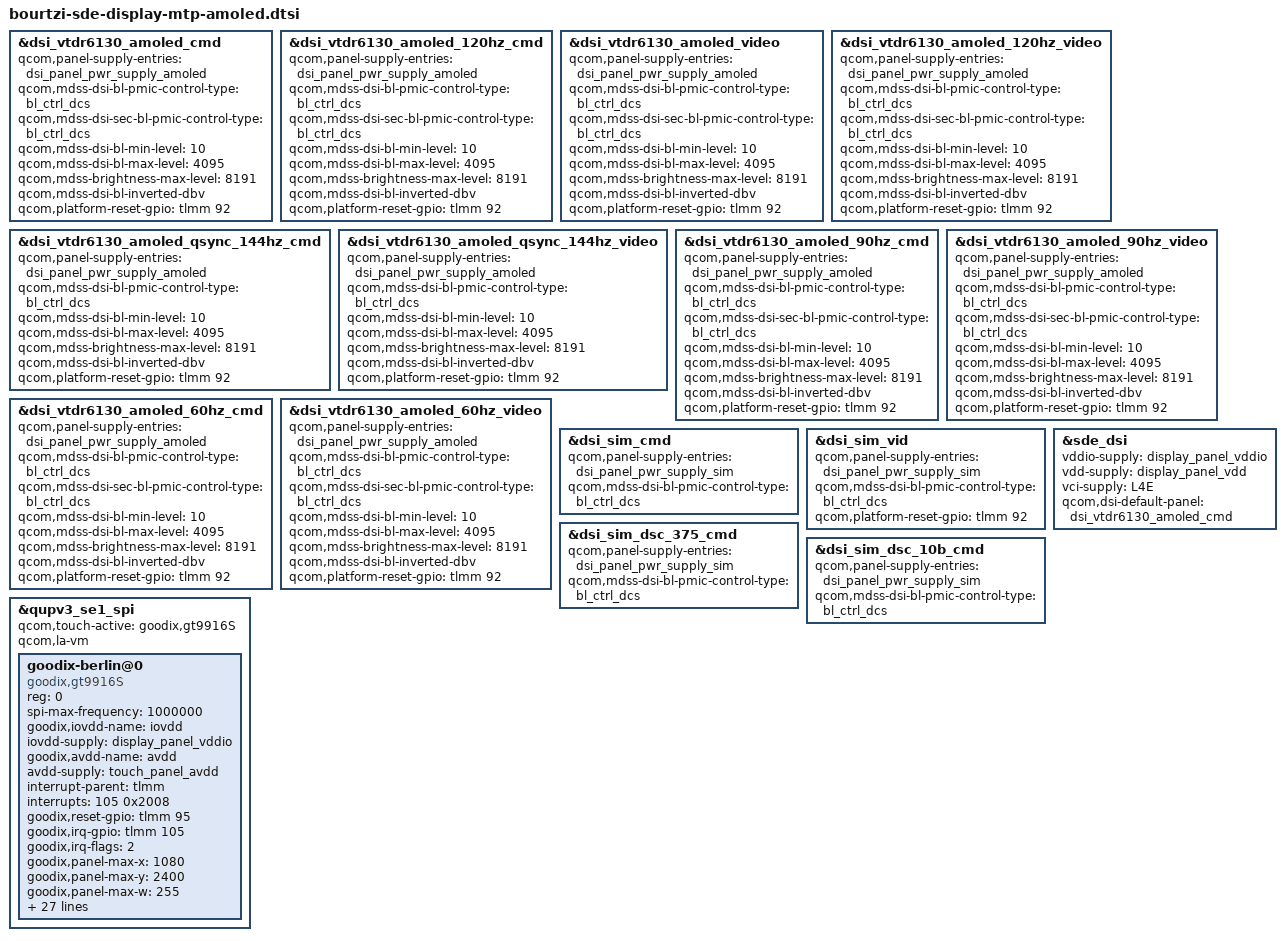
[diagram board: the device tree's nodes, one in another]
// SPDX-License-Identifier: BSD-3-Clause
/*
 * Copyright (c) Qualcomm Technologies, Inc. and/or its subsidiaries.
 */

#include "bourtzi-sde-display.dtsi"

&dsi_vtdr6130_amoled_cmd {
	qcom,panel-supply-entries = <&dsi_panel_pwr_supply_amoled>;
	qcom,mdss-dsi-bl-pmic-control-type = "bl_ctrl_dcs";
	qcom,mdss-dsi-sec-bl-pmic-control-type = "bl_ctrl_dcs";
	qcom,mdss-dsi-bl-min-level = <10>;
	qcom,mdss-dsi-bl-max-level = <4095>;
	qcom,mdss-brightness-max-level = <8191>;
	qcom,mdss-dsi-bl-inverted-dbv;
	qcom,platform-reset-gpio = <&tlmm 92 0>;
};

&dsi_vtdr6130_amoled_120hz_cmd {
	qcom,panel-supply-entries = <&dsi_panel_pwr_supply_amoled>;
	qcom,mdss-dsi-bl-pmic-control-type = "bl_ctrl_dcs";
	qcom,mdss-dsi-sec-bl-pmic-control-type = "bl_ctrl_dcs";
	qcom,mdss-dsi-bl-min-level = <10>;
	qcom,mdss-dsi-bl-max-level = <4095>;
	qcom,mdss-brightness-max-level = <8191>;
	qcom,mdss-dsi-bl-inverted-dbv;
	qcom,platform-reset-gpio = <&tlmm 92 0>;
};

&dsi_vtdr6130_amoled_video {
	qcom,panel-supply-entries = <&dsi_panel_pwr_supply_amoled>;
	qcom,mdss-dsi-bl-pmic-control-type = "bl_ctrl_dcs";
	qcom,mdss-dsi-sec-bl-pmic-control-type = "bl_ctrl_dcs";
	qcom,mdss-dsi-bl-min-level = <10>;
	qcom,mdss-dsi-bl-max-level = <4095>;
	qcom,mdss-brightness-max-level = <8191>;
	qcom,mdss-dsi-bl-inverted-dbv;
	qcom,platform-reset-gpio = <&tlmm 92 0>;
};

&dsi_vtdr6130_amoled_120hz_video {
	qcom,panel-supply-entries = <&dsi_panel_pwr_supply_amoled>;
	qcom,mdss-dsi-bl-pmic-control-type = "bl_ctrl_dcs";
	qcom,mdss-dsi-sec-bl-pmic-control-type = "bl_ctrl_dcs";
	qcom,mdss-dsi-bl-min-level = <10>;
	qcom,mdss-dsi-bl-max-level = <4095>;
	qcom,mdss-brightness-max-level = <8191>;
	qcom,mdss-dsi-bl-inverted-dbv;
	qcom,platform-reset-gpio = <&tlmm 92 0>;
};

&dsi_vtdr6130_amoled_qsync_144hz_cmd {
	qcom,panel-supply-entries = <&dsi_panel_pwr_supply_amoled>;
	qcom,mdss-dsi-bl-pmic-control-type = "bl_ctrl_dcs";
	qcom,mdss-dsi-bl-min-level = <10>;
	qcom,mdss-dsi-bl-max-level = <4095>;
	qcom,mdss-brightness-max-level = <8191>;
	qcom,mdss-dsi-bl-inverted-dbv;
	qcom,platform-reset-gpio = <&tlmm 92 0>;
};

&dsi_vtdr6130_amoled_qsync_144hz_video {
	qcom,panel-supply-entries = <&dsi_panel_pwr_supply_amoled>;
	qcom,mdss-dsi-bl-pmic-control-type = "bl_ctrl_dcs";
	qcom,mdss-dsi-bl-min-level = <10>;
	qcom,mdss-dsi-bl-max-level = <4095>;
	qcom,mdss-brightness-max-level = <8191>;
	qcom,mdss-dsi-bl-inverted-dbv;
	qcom,platform-reset-gpio = <&tlmm 92 0>;
};

&dsi_vtdr6130_amoled_90hz_cmd {
	qcom,panel-supply-entries = <&dsi_panel_pwr_supply_amoled>;
	qcom,mdss-dsi-bl-pmic-control-type = "bl_ctrl_dcs";
	qcom,mdss-dsi-sec-bl-pmic-control-type = "bl_ctrl_dcs";
	qcom,mdss-dsi-bl-min-level = <10>;
	qcom,mdss-dsi-bl-max-level = <4095>;
	qcom,mdss-brightness-max-level = <8191>;
	qcom,mdss-dsi-bl-inverted-dbv;
	qcom,platform-reset-gpio = <&tlmm 92 0>;
};

&dsi_vtdr6130_amoled_90hz_video {
	qcom,panel-supply-entries = <&dsi_panel_pwr_supply_amoled>;
	qcom,mdss-dsi-bl-pmic-control-type = "bl_ctrl_dcs";
	qcom,mdss-dsi-sec-bl-pmic-control-type = "bl_ctrl_dcs";
	qcom,mdss-dsi-bl-min-level = <10>;
	qcom,mdss-dsi-bl-max-level = <4095>;
	qcom,mdss-brightness-max-level = <8191>;
	qcom,mdss-dsi-bl-inverted-dbv;
	qcom,platform-reset-gpio = <&tlmm 92 0>;
};

&dsi_vtdr6130_amoled_60hz_cmd {
	qcom,panel-supply-entries = <&dsi_panel_pwr_supply_amoled>;
	qcom,mdss-dsi-bl-pmic-control-type = "bl_ctrl_dcs";
	qcom,mdss-dsi-sec-bl-pmic-control-type = "bl_ctrl_dcs";
	qcom,mdss-dsi-bl-min-level = <10>;
	qcom,mdss-dsi-bl-max-level = <4095>;
	qcom,mdss-brightness-max-level = <8191>;
	qcom,mdss-dsi-bl-inverted-dbv;
	qcom,platform-reset-gpio = <&tlmm 92 0>;
};

&dsi_vtdr6130_amoled_60hz_video {
	qcom,panel-supply-entries = <&dsi_panel_pwr_supply_amoled>;
	qcom,mdss-dsi-bl-pmic-control-type = "bl_ctrl_dcs";
	qcom,mdss-dsi-sec-bl-pmic-control-type = "bl_ctrl_dcs";
	qcom,mdss-dsi-bl-min-level = <10>;
	qcom,mdss-dsi-bl-max-level = <4095>;
	qcom,mdss-brightness-max-level = <8191>;
	qcom,mdss-dsi-bl-inverted-dbv;
	qcom,platform-reset-gpio = <&tlmm 92 0>;
};

&dsi_sim_cmd {
	qcom,panel-supply-entries = <&dsi_panel_pwr_supply_sim>;
	qcom,mdss-dsi-bl-pmic-control-type = "bl_ctrl_dcs";
};

&dsi_sim_vid {
	qcom,panel-supply-entries = <&dsi_panel_pwr_supply_sim>;
	qcom,mdss-dsi-bl-pmic-control-type = "bl_ctrl_dcs";
	qcom,platform-reset-gpio = <&tlmm 92 0>;
};

&dsi_sim_dsc_375_cmd {
	qcom,panel-supply-entries = <&dsi_panel_pwr_supply_sim>;
	qcom,mdss-dsi-bl-pmic-control-type = "bl_ctrl_dcs";
};

&dsi_sim_dsc_10b_cmd {
	qcom,panel-supply-entries = <&dsi_panel_pwr_supply_sim>;
	qcom,mdss-dsi-bl-pmic-control-type = "bl_ctrl_dcs";
};

&sde_dsi {
	vddio-supply = <&display_panel_vddio>;
	vdd-supply = <&display_panel_vdd>;
	vci-supply = <&L4E>;

	qcom,dsi-default-panel = <&dsi_vtdr6130_amoled_cmd>;
};

&qupv3_se1_spi {
	#address-cells = <1>;
	#size-cells = <0>;
	status = "ok";
	qcom,touch-active = "goodix,gt9916S";
	qcom,la-vm;

	goodix-berlin@0 {
		compatible = "goodix,gt9916S";
		reg = <0>;
		spi-max-frequency = <1000000>;

		goodix,iovdd-name = "iovdd";
		iovdd-supply = <&display_panel_vddio>;
		goodix,avdd-name = "avdd";
		avdd-supply = <&touch_panel_avdd>;

		interrupt-parent = <&tlmm>;
		interrupts = <105 0x2008>;
		goodix,reset-gpio = <&tlmm 95 0x00>;
		goodix,irq-gpio = <&tlmm 105 0x2008>;
		goodix,irq-flags = <2>;
		goodix,panel-max-x = <1080>;
		goodix,panel-max-y = <2400>;
		goodix,panel-max-w = <255>;
		goodix,panel-max-p = <4096>;
		goodix,firmware-name = "goodix_firmware_spi.bin";
		goodix,config-name = "goodix_cfg_group_spi.bin";

		pinctrl-names = "pmx_ts_active", "pmx_ts_suspend", "pmx_ts_release";
		pinctrl-0 = <&ts_active>;
		pinctrl-1 = <&ts_int_suspend &ts_reset_suspend>;
		pinctrl-2 = <&ts_release>;

		goodix,touch-type = "primary";
		goodix,qts_en;

		qts,trusted-touch-mode = "vm_mode";
		qts,touch-environment = "pvm";
		qts,trusted-touch-type = "primary";
		qts,trusted-touch-spi-irq = <570>;
		qts,trusted-touch-io-bases = <0x984000>;
		qts,trusted-touch-io-sizes = <0x1000>;
		qts,trusted-touch-vm-gpio-list = <&tlmm 10 0 &tlmm 11 0 &tlmm 12 0
						&tlmm 13 0 &tlmm 95 0 &tlmm 105 0x2008>;
		panel = <&dsi_vtdr6130_amoled_cmd
			&dsi_vtdr6130_amoled_120hz_cmd
			&dsi_vtdr6130_amoled_video
			&dsi_vtdr6130_amoled_120hz_video
			&dsi_vtdr6130_amoled_qsync_144hz_cmd
			&dsi_vtdr6130_amoled_qsync_144hz_video
			&dsi_vtdr6130_amoled_90hz_cmd
			&dsi_vtdr6130_amoled_90hz_video
			&dsi_vtdr6130_amoled_60hz_cmd
			&dsi_vtdr6130_amoled_60hz_video>;
	};
};
